# ESP32S31_RADIO register map
Vendor: Espressif; Series: ESP32-S31; File version: 3.52
Registers are 32-bit, read-write, no defined reset value unless marked. A register's access mark holds for its fields unless they carry their own. Offsets are from the block's base; [hi:lo] are bit positions; lines under a group give offsets from that group; 'fields as' and 'values as' point back to an identical list.

## PHY_PBUS — PBus command, mode, status/clock/force and packed result windows recovered from complete rev0 ROM bodies and their address/shift jump tables. The blob debug printer independently names selector/path groups: RFRX is selector 0 paths 1/2; BB is selector 1 paths 1/2; DCO is selectors 2/3 paths 1/2; RFTX is selector 4 paths 1/2 and selector 5 path 1.
Base 0x20100880
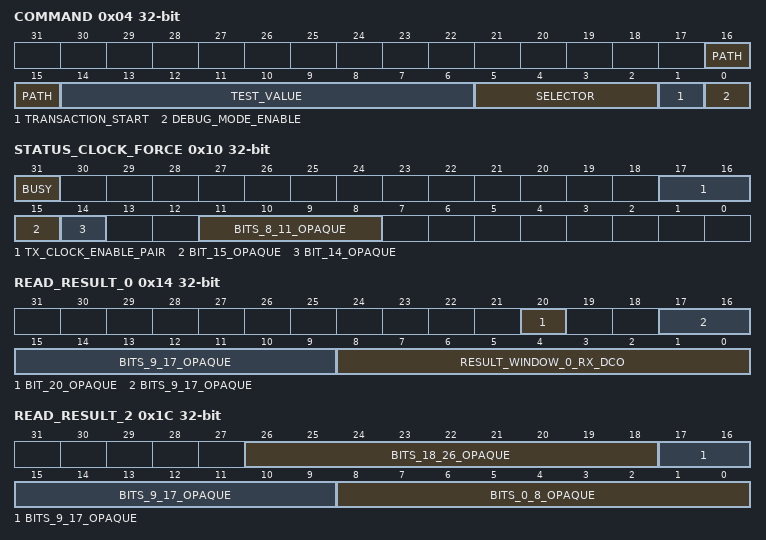
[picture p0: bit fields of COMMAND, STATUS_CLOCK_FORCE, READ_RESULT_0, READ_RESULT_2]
0x04 COMMAND — Project-assigned name. phy_pbus_force_test command word; phy_pbus_force_mode also uses bit 0 as the debug/work selector. The complete force-test body at 0x2f824228 composes selector, test value and path first, then masks the combined image with 0x0001fffc. It does not independently narrow the signed halfword values supplied by phy_pbus_rx_dco_cal at 0x2f828f44, so their retained high bits can contribute to the physical PATH field.
  [16:15] PATH — Project-assigned name. Physical two-bit path field. High retained bits of a wide test-value argument are ORed into this field by the complete ROM command encoder. The debug printer exercises paths 1 and 2 for RFRX, BB, DCO and selector-4 RFTX, and path 1 for selector-5 RFTX.
  [14:6] TEST_VALUE — Project-assigned name. Physical nine-bit value field. The ROM publication expression accepts a wider signed halfword before the combined command mask; use the PAC ROM encoder when reproducing that behavior.
  [5:2] SELECTOR — Project-assigned name. Debug group selector: 0 RFRX, 1 BB, 2/3 DCO, 4/5 RFTX for the evidenced paths. Treat other selector/path combinations as undocumented.
  [1] TRANSACTION_START — Project-assigned name.
  [0] DEBUG_MODE_ENABLE — Project-assigned name.
0x0C MODE — Project-assigned name. PBus debug/work mode selector used by complete phy_pbus_force_mode.
  [26] WORK_MODE_ENABLE — Project-assigned name.
0x10 STATUS_CLOCK_FORCE — Project-assigned name. One physical multifunction word independently used for TX/RX forcing, RX/TX clock pairs and PBus busy status.
  [31] BUSY — Project-assigned name.
  [17:16] TX_CLOCK_ENABLE_PAIR — Project-assigned name. phy_set_txclk_en writes both bits as a pair; individual clock identities are unknown.
    on write: 0=DISABLED (Disable both recovered TX clock bits.); 3=ENABLED (Enable both recovered TX clock bits.)
  [15] BIT_15_OPAQUE — Opaque: meaning not established. phy_set_rxclk_en writes this bit with its neighbor as a pair; complete phy_rxiq_cal_init independently sets it at root entry and clears it during the successful cleanup suffix. The shared electrical identity remains unknown.
  [14] BIT_14_OPAQUE — Opaque: meaning not established. phy_set_rxclk_en writes this bit with its neighbor as a pair; complete phy_rxiq_cal_init independently sets it first at root entry. The shared electrical identity remains unknown.
  [11:8] BITS_8_11_OPAQUE — Opaque: meaning not established. phy_force_txrx_off replaces bits 11:8 with one of four evidenced encodings; the individual bit meanings remain unknown.
    on write: 8=ENABLE_INITIAL_PHASE (First force-TX/RX enable write in complete phy_force_txrx_off.); 10=ENABLE_FINAL_PHASE (Second force-TX/RX enable write in complete phy_force_txrx_off.); 2=DISABLE_INITIAL_PHASE (First force-TX/RX disable write in complete phy_force_txrx_off.); 0=DISABLE_FINAL_PHASE (Second force-TX/RX disable write in complete phy_force_txrx_off.)
0x14 READ_RESULT_0 — Project-assigned name. Shared PBus/FE word. Selector 1 reads result window 0 for non-path-1 operations, including RX-DCO, and window 1 for path 1. Complete phy_fe_reg_init independently sets bit 20 through a fresh-read RMW.
  [20] BIT_20_OPAQUE — Opaque: meaning not established. First complete phy_fe_reg_init RMW sets bit 20.
  [17:9] BITS_9_17_OPAQUE ro — Opaque: meaning not established.
  [8:0] RESULT_WINDOW_0_RX_DCO ro — Project-assigned name.
0x18 READ_RESULT_1 ro — Project-assigned name. Selector 2 path 1 reads window 0; other bits are not presently evidenced.
  [8:0] BITS_0_8_OPAQUE — Opaque: meaning not established.
0x1C READ_RESULT_2 ro — Project-assigned name. Selector 3 reads windows 0/1; selector 2 non-path-1 reads window 2.
  [26:18] BITS_18_26_OPAQUE — Opaque: meaning not established.
  [17:9] BITS_9_17_OPAQUE — Opaque: meaning not established.
  [8:0] BITS_0_8_OPAQUE — Opaque: meaning not established.
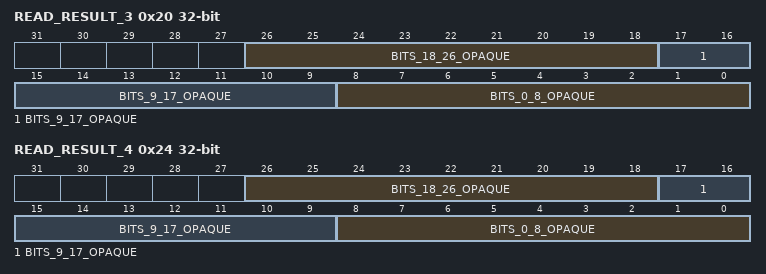
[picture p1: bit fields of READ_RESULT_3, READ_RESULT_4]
0x20 READ_RESULT_3 ro — Project-assigned name. Selector 4 path 1 reads window 0; selector 0 non-path-one reads window 1 and path one reads window 2.
  fields as READ_RESULT_2
0x24 READ_RESULT_4 ro — Project-assigned name. Selectors above five fall back to window 0, selector 5 reads window 1, and selector 4 non-path-one reads window 2.
  fields as READ_RESULT_2
